# Espressif register map
File version: 1.0
CPU: Xtensa LX6 1, little endian, no MPU, FPU, 3 interrupt priority bits
Registers are 32-bit, access not given, reset 0x0 unless marked. A register's access mark holds for its fields unless they carry their own. Offsets are from the block's base; [hi:lo] are bit positions; {n}, {i} and the like mark numbered series; 'fields as' and 'values as' point back to an identical list.

## TIMG
Base 0x00000000
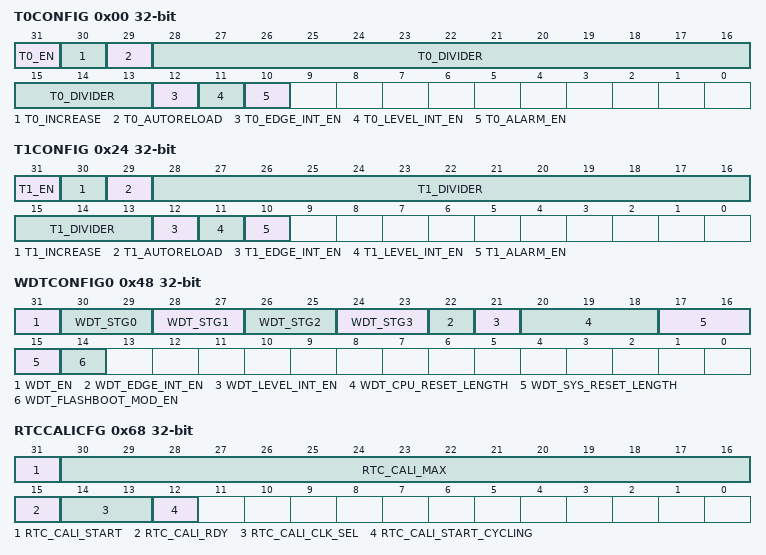
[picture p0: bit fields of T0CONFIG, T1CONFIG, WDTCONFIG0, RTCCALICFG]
0x00 T0CONFIG — TIMG_T0CONFIG
  [31] T0_EN, [30] T0_INCREASE, [29] T0_AUTORELOAD, [28:13] T0_DIVIDER, [12] T0_EDGE_INT_EN, [11] T0_LEVEL_INT_EN, [10] T0_ALARM_EN
0x04 T0LO — TIMG_T0LO
  [31:0] T0_LO
0x08 T0HI — TIMG_T0HI
  [31:0] T0_HI
0x0C T0UPDATE — TIMG_T0UPDATE
  [31:0] T0_UPDATE
0x10 T0ALARMLO — TIMG_T0ALARMLO
  [31:0] T0_ALARM_LO
0x14 T0ALARMHI — TIMG_T0ALARMHI
  [31:0] T0_ALARM_HI
0x18 T0LOADLO — TIMG_T0LOADLO
  [31:0] T0_LOAD_LO
0x1C T0LOADHI — TIMG_T0LOADHI
  [31:0] T0_LOAD_HI
0x20 T0LOAD — TIMG_T0LOAD
  [31:0] T0_LOAD
0x24 T1CONFIG — TIMG_T1CONFIG
  [31] T1_EN, [30] T1_INCREASE, [29] T1_AUTORELOAD, [28:13] T1_DIVIDER, [12] T1_EDGE_INT_EN, [11] T1_LEVEL_INT_EN, [10] T1_ALARM_EN
0x28 T1LO — TIMG_T1LO
  [31:0] T1_LO
0x2C T1HI — TIMG_T1HI
  [31:0] T1_HI
0x30 T1UPDATE — TIMG_T1UPDATE
  [31:0] T1_UPDATE
0x34 T1ALARMLO — TIMG_T1ALARMLO
  [31:0] T1_ALARM_LO
0x38 T1ALARMHI — TIMG_T1ALARMHI
  [31:0] T1_ALARM_HI
0x3C T1LOADLO — TIMG_T1LOADLO
  [31:0] T1_LOAD_LO
0x40 T1LOADHI — TIMG_T1LOADHI
  [31:0] T1_LOAD_HI
0x44 T1LOAD — TIMG_T1LOAD
  [31:0] T1_LOAD
0x48 WDTCONFIG0 — TIMG_WDTCONFIG0
  [31] WDT_EN, [30-2n:29-2n] WDT_STG{n} (n=0..3), [22] WDT_EDGE_INT_EN, [21] WDT_LEVEL_INT_EN, [20:18] WDT_CPU_RESET_LENGTH, [17:15] WDT_SYS_RESET_LENGTH, [14] WDT_FLASHBOOT_MOD_EN
0x4C WDTCONFIG1 — TIMG_WDTCONFIG1
  [31:16] WDT_CLK_PRESCALE
{0x48+4i} WDTCONFIG{i} (i=2..5) — TIMG_WDTCONFIG{i}
  [31:0] WDT_STG{i-2}_HOLD
0x60 WDTFEED — TIMG_WDTFEED
  [31:0] WDT_FEED
0x64 WDTWPROTECT — TIMG_WDTWPROTECT
  [31:0] WDT_WKEY
0x68 RTCCALICFG — TIMG_RTCCALICFG
  [31] RTC_CALI_START, [30:16] RTC_CALI_MAX, [15] RTC_CALI_RDY, [14:13] RTC_CALI_CLK_SEL, [12] RTC_CALI_START_CYCLING
0x6C RTCCALICFG1 — TIMG_RTCCALICFG1
  [31:7] RTC_CALI_VALUE
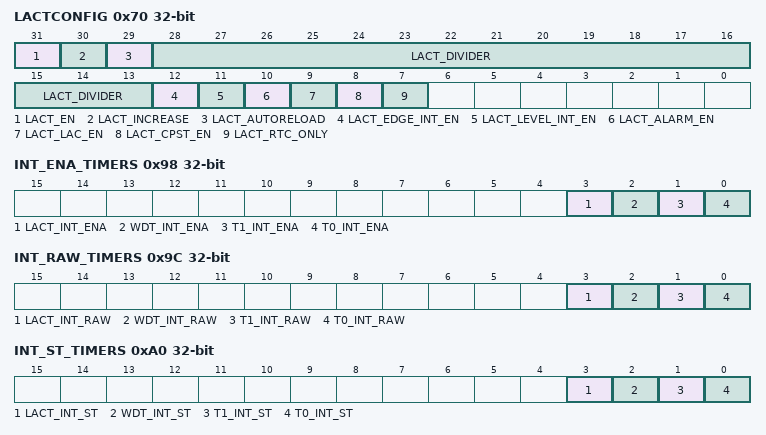
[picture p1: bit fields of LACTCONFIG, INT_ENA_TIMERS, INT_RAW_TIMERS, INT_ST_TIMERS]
0x70 LACTCONFIG — TIMG_LACTCONFIG
  [31] LACT_EN, [30] LACT_INCREASE, [29] LACT_AUTORELOAD, [28:13] LACT_DIVIDER, [12] LACT_EDGE_INT_EN, [11] LACT_LEVEL_INT_EN, [10] LACT_ALARM_EN, [9] LACT_LAC_EN, [8] LACT_CPST_EN, [7] LACT_RTC_ONLY
0x74 LACTRTC — TIMG_LACTRTC
  [31:6] LACT_RTC_STEP_LEN
0x78 LACTLO — TIMG_LACTLO
  [31:0] LACT_LO
0x7C LACTHI — TIMG_LACTHI
  [31:0] LACT_HI
0x80 LACTUPDATE — TIMG_LACTUPDATE
  [31:0] LACT_UPDATE
0x84 LACTALARMLO — TIMG_LACTALARMLO
  [31:0] LACT_ALARM_LO
0x88 LACTALARMHI — TIMG_LACTALARMHI
  [31:0] LACT_ALARM_HI
0x8C LACTLOADLO — TIMG_LACTLOADLO
  [31:0] LACT_LOAD_LO
0x90 LACTLOADHI — TIMG_LACTLOADHI
  [31:0] LACT_LOAD_HI
0x94 LACTLOAD — TIMG_LACTLOAD
  [31:0] LACT_LOAD
0x98 INT_ENA_TIMERS — TIMG_INT_ENA_TIMERS
  [3] LACT_INT_ENA, [2] WDT_INT_ENA, [1] T1_INT_ENA, [0] T0_INT_ENA
0x9C INT_RAW_TIMERS — TIMG_INT_RAW_TIMERS
  [3] LACT_INT_RAW, [2] WDT_INT_RAW, [1] T1_INT_RAW, [0] T0_INT_RAW
0xA0 INT_ST_TIMERS — TIMG_INT_ST_TIMERS
  [3] LACT_INT_ST, [2] WDT_INT_ST, [1] T1_INT_ST, [0] T0_INT_ST
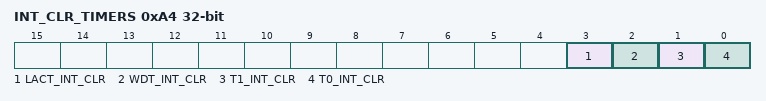
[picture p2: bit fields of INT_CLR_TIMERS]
0xA4 INT_CLR_TIMERS — TIMG_INT_CLR_TIMERS
  [3] LACT_INT_CLR, [2] WDT_INT_CLR, [1] T1_INT_CLR, [0] T0_INT_CLR
0xF8 NTIMERS_DATE — TIMG_NTIMERS_DATE
  [27:0] NTIMERS_DATE
0xFC TIMGCLK
  [31] CLK_EN

## GPIO_SD
Base 0x3FF44F00
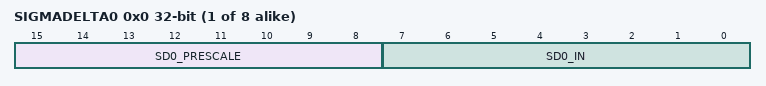
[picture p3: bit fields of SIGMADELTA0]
{0x0+4i} SIGMADELTA{i} (i=0..7) — GPIO_SIGMADELTA{i}
  [15:8] SD{i}_PRESCALE, [7:0] SD{i}_IN
0x20 SIGMADELTA_CG — GPIO_SIGMADELTA_CG
  [31] SD_CLK_EN
0x24 SIGMADELTA_MISC — GPIO_SIGMADELTA_MISC
  [31] SPI_SWAP
0x28 SIGMADELTA_VERSION — GPIO_SIGMADELTA_VERSION
  [27:0] SD_DATE

## IO_MUX
Base 0x3FF49000
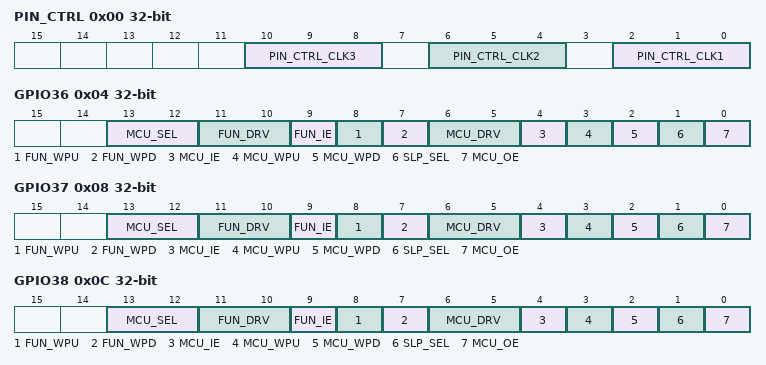
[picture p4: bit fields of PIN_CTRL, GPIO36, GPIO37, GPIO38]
0x00 PIN_CTRL — IO_MUX_PIN_CTRL
  [10:8] PIN_CTRL_CLK3, [6:4] PIN_CTRL_CLK2, [2:0] PIN_CTRL_CLK1
0x04 GPIO36 — IO_MUX_GPIO36_REG
  [13:12] MCU_SEL, [11:10] FUN_DRV, [9] FUN_IE, [8] FUN_WPU, [7] FUN_WPD, [6:5] MCU_DRV, [4] MCU_IE, [3] MCU_WPU, [2] MCU_WPD, [1] SLP_SEL, [0] MCU_OE
0x08 GPIO37 — IO_MUX_GPIO37_REG
  fields as GPIO36
0x0C GPIO38 — IO_MUX_GPIO38_REG
  fields as GPIO36
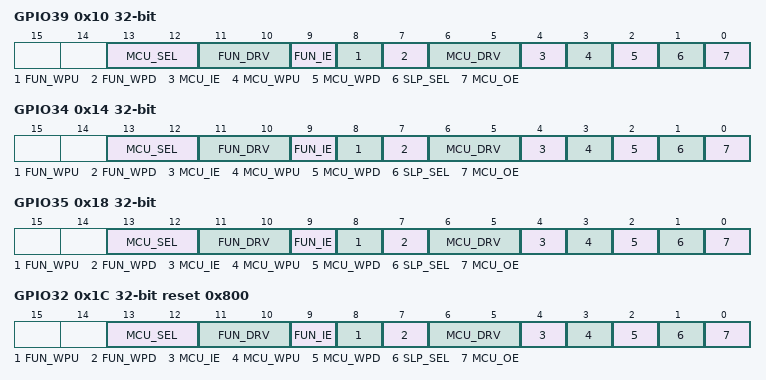
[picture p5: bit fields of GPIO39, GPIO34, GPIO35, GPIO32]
0x10 GPIO39 — IO_MUX_GPIO39_REG
  fields as GPIO36
0x14 GPIO34 — IO_MUX_GPIO34_REG
  fields as GPIO36
0x18 GPIO35 — IO_MUX_GPIO35_REG
  fields as GPIO36
0x1C GPIO32 reset 0x800 — IO_MUX_GPIO32_REG
  fields as GPIO36
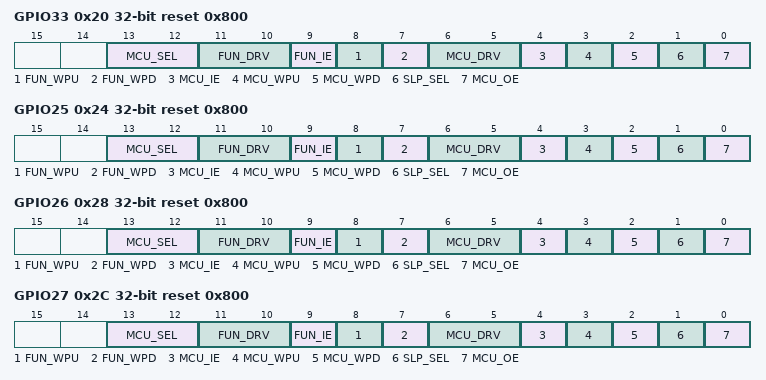
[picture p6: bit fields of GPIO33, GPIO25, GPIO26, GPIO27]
0x20 GPIO33 reset 0x800 — IO_MUX_GPIO33_REG
  fields as GPIO36
0x24 GPIO25 reset 0x800 — IO_MUX_GPIO25_REG
  fields as GPIO36
0x28 GPIO26 reset 0x800 — IO_MUX_GPIO26_REG
  fields as GPIO36
0x2C GPIO27 reset 0x800 — IO_MUX_GPIO27_REG
  fields as GPIO36
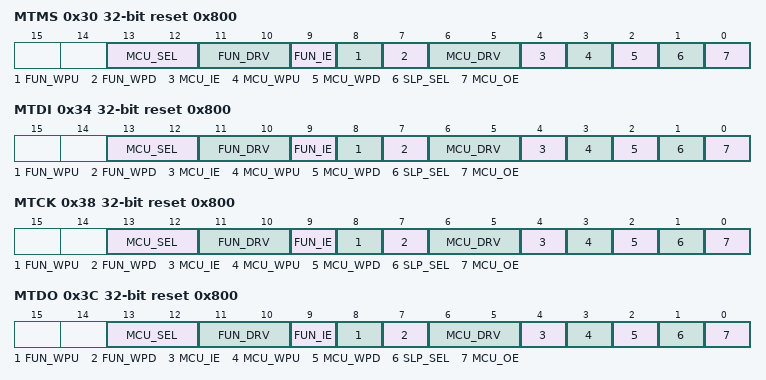
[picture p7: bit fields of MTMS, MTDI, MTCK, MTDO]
0x30 MTMS reset 0x800 — IO_MUX_MTMS_REG
  fields as GPIO36
0x34 MTDI reset 0x800 — IO_MUX_MTDI_REG
  fields as GPIO36
0x38 MTCK reset 0x800 — IO_MUX_MTCK_REG
  fields as GPIO36
0x3C MTDO reset 0x800 — IO_MUX_MTDO_REG
  fields as GPIO36
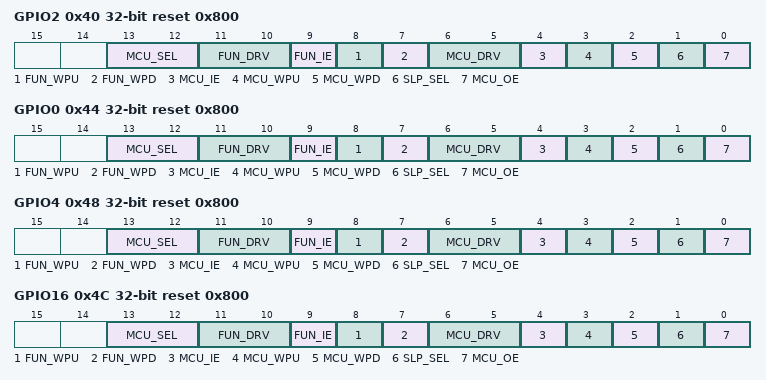
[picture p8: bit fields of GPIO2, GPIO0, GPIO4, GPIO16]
0x40 GPIO2 reset 0x800 — IO_MUX_GPIO2_REG
  fields as GPIO36
0x44 GPIO0 reset 0x800 — IO_MUX_GPIO0_REG
  fields as GPIO36
0x48 GPIO4 reset 0x800 — IO_MUX_GPIO4_REG
  fields as GPIO36
0x4C GPIO16 reset 0x800 — IO_MUX_GPIO16_REG
  fields as GPIO36
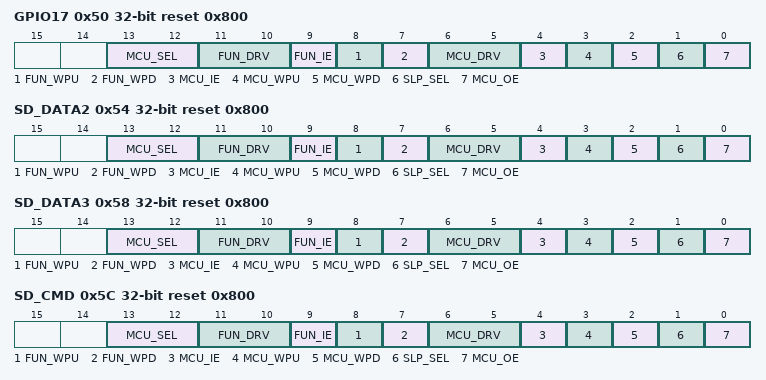
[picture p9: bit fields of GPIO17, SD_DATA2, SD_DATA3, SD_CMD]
0x50 GPIO17 reset 0x800 — IO_MUX_GPIO17_REG
  fields as GPIO36
0x54 SD_DATA2 reset 0x800 — IO_MUX_SD_DATA2_REG
  fields as GPIO36
0x58 SD_DATA3 reset 0x800 — IO_MUX_SD_DATA3_REG
  fields as GPIO36
0x5C SD_CMD reset 0x800 — IO_MUX_SD_CMD_REG
  fields as GPIO36
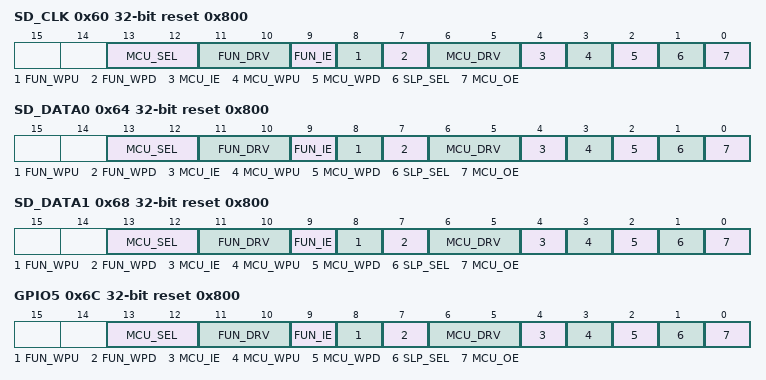
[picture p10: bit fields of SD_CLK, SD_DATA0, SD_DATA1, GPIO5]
0x60 SD_CLK reset 0x800 — IO_MUX_SD_CLK_REG
  fields as GPIO36
0x64 SD_DATA0 reset 0x800 — IO_MUX_SD_DATA0_REG
  fields as GPIO36
0x68 SD_DATA1 reset 0x800 — IO_MUX_SD_DATA1_REG
  fields as GPIO36
0x6C GPIO5 reset 0x800 — IO_MUX_GPIO5_REG
  fields as GPIO36
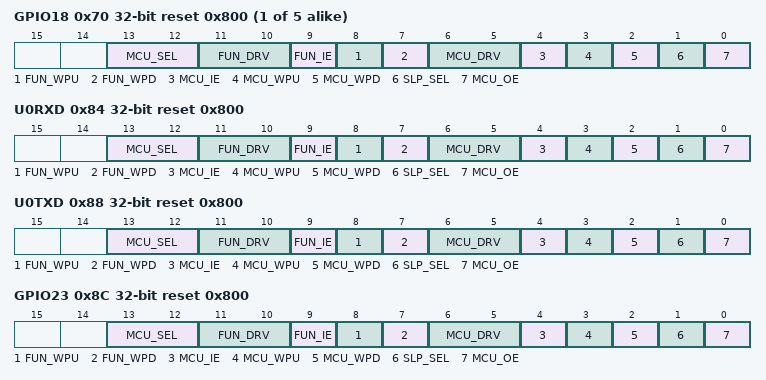
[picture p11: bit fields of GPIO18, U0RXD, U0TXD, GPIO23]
{0x28+4i} GPIO{i} reset 0x800 (i=18..22) — IO_MUX_GPIO{i}_REG
  fields as GPIO36
0x84 U0RXD reset 0x800 — IO_MUX_U0RXD_REG
  fields as GPIO36
0x88 U0TXD reset 0x800 — IO_MUX_U0TXD_REG
  fields as GPIO36
0x8C GPIO23 reset 0x800 — IO_MUX_GPIO23_REG
  fields as GPIO36
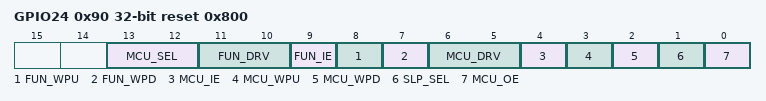
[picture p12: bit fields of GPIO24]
0x90 GPIO24 reset 0x800 — IO_MUX_GPIO24_REG
  fields as GPIO36
